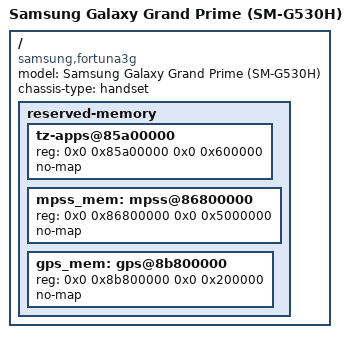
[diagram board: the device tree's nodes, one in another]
// SPDX-License-Identifier: GPL-2.0-only

/dts-v1/;

#include "msm8916-samsung-gprime-common.dtsi"

/ {
	model = "Samsung Galaxy Grand Prime (SM-G530H)";
	compatible = "samsung,fortuna3g", "samsung,gprime", "qcom,msm8916";
	chassis-type = "handset";

	reserved-memory {
		/* Additional memory used by Samsung firmware modifications */
		tz-apps@85a00000 {
			reg = <0x0 0x85a00000 0x0 0x600000>;
			no-map;
		};

		mpss_mem: mpss@86800000 {
			reg = <0x0 0x86800000 0x0 0x5000000>;
			no-map;
		};

		gps_mem: gps@8b800000 {
			reg = <0x0 0x8b800000 0x0 0x200000>;
			no-map;
		};
	};
};
